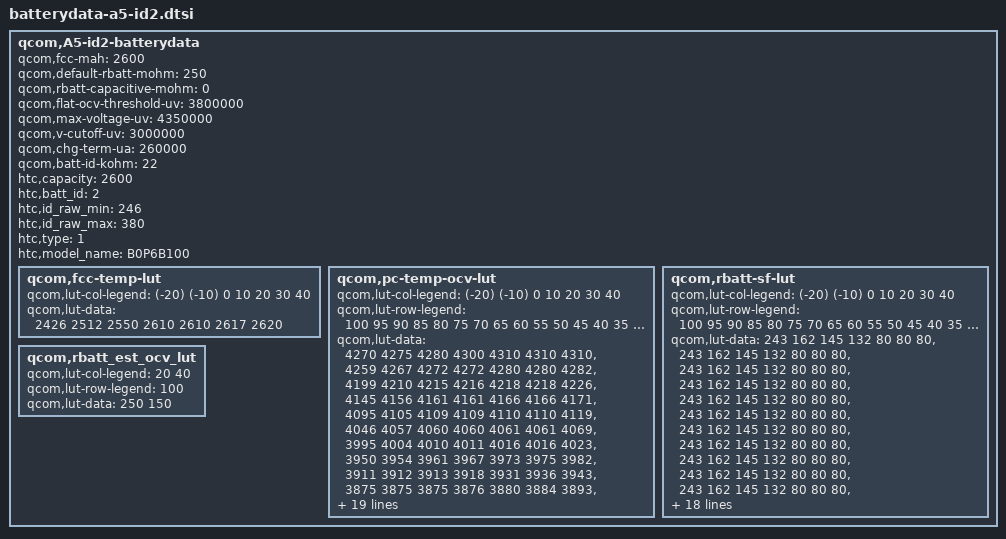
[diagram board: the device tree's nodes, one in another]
qcom,A5-id2-batterydata {
	qcom,fcc-mah = <2600>;
	qcom,default-rbatt-mohm = <250>;
	qcom,rbatt-capacitive-mohm = <0>;
	qcom,flat-ocv-threshold-uv = <3800000>;
	qcom,max-voltage-uv = <4350000>;
	qcom,v-cutoff-uv = <3000000>;
	qcom,chg-term-ua = <260000>;
	qcom,batt-id-kohm = <22>;
	htc,capacity = <2600>;
	htc,batt_id = <2>;
	htc,id_raw_min = <246>;
	htc,id_raw_max = <380>;
	htc,type = <1>;
	htc,model_name = "B0P6B100";

	qcom,fcc-temp-lut {
		qcom,lut-col-legend = <(-20) (-10) 0 10 20 30 40>;
		qcom,lut-data = <2426 2512 2550 2610 2610 2617 2620>;
	};

	qcom,pc-temp-ocv-lut {
		qcom,lut-col-legend = <(-20) (-10) 0 10 20 30 40>;
		qcom,lut-row-legend = <100 95 90 85 80 75 70 65 60 55 50 45 40 35 30 25 20 15 10 9 8 7 6 5 4 3 2 1 0>;
		qcom,lut-data = <4270 4275 4280 4300 4310 4310 4310>,
				<4259 4267 4272 4272 4280 4280 4282>,
				<4199 4210 4215 4216 4218 4218 4226>,
				<4145 4156 4161 4161 4166 4166 4171>,
				<4095 4105 4109 4109 4110 4110 4119>,
				<4046 4057 4060 4060 4061 4061 4069>,
				<3995 4004 4010 4011 4016 4016 4023>,
				<3950 3954 3961 3967 3973 3975 3982>,
				<3911 3912 3913 3918 3931 3936 3943>,
				<3875 3875 3875 3876 3880 3884 3893>,
				<3845 3845 3845 3845 3846 3849 3855>,
				<3822 3822 3822 3822 3825 3825 3830>,
				<3802 3802 3802 3802 3807 3807 3811>,
				<3786 3786 3786 3787 3792 3792 3794>,
				<3773 3773 3773 3773 3777 3777 3779>,
				<3757 3762 3762 3762 3762 3762 3764>,
				<3739 3739 3739 3739 3739 3739 3739>,
				<3710 3710 3710 3708 3708 3708 3708>,
				<3689 3689 3689 3689 3689 3689 3689>,
				<3684 3684 3684 3684 3681 3681 3681>,
				<3679 3679 3679 3679 3674 3674 3674>,
				<3673 3673 3673 3673 3667 3667 3667>,
				<3667 3667 3667 3668 3660 3660 3660>,
				<3662 3662 3662 3662 3653 3653 3653>,
				<3620 3580 3560 3543 3543 3543 3543>,
				<3520 3480 3450 3420 3420 3420 3420>,
				<3390 3350 3330 3290 3290 3290 3290>,
				<3220 3200 3180 3150 3150 3150 3150>,
				<3000 3000 3000 3000 3000 3000 3000>;
	};

	qcom,rbatt-sf-lut {
		qcom,lut-col-legend = <(-20) (-10) 0 10 20 30 40>;
		qcom,lut-row-legend = <100 95 90 85 80 75 70 65 60 55 50 45 40 35 30 25 20 15 10 9 8 7 6 5 4 3 2 1 0>;
		qcom,lut-data = <243 162 145 132 80 80 80>,
				<243 162 145 132 80 80 80>,
				<243 162 145 132 80 80 80>,
				<243 162 145 132 80 80 80>,
				<243 162 145 132 80 80 80>,
				<243 162 145 132 80 80 80>,
				<243 162 145 132 80 80 80>,
				<243 162 145 132 80 80 80>,
				<243 162 145 132 80 80 80>,
				<243 162 145 132 80 80 80>,
				<243 162 145 132 80 80 80>,
				<243 162 145 132 80 80 80>,
				<243 162 145 132 80 80 80>,
				<243 162 145 132 80 80 80>,
				<243 162 145 132 80 80 80>,
				<243 162 145 132 80 80 80>,
				<243 162 145 132 80 80 80>,
				<243 162 145 132 80 80 80>,
				<243 162 145 132 80 80 80>,
				<243 162 145 132 80 80 80>,
				<243 162 145 132 80 80 80>,
				<243 162 145 132 80 80 80>,
				<243 162 145 132 80 80 80>,
				<243 162 145 132 80 80 80>,
				<243 162 145 132 80 80 80>,
				<243 162 145 132 80 80 80>,
				<243 162 145 132 80 80 80>,
				<243 162 145 132 80 80 80>,
				<243 162 145 132 80 80 80>;
	};

	qcom,rbatt_est_ocv_lut {
		qcom,lut-col-legend = <20 40>;
		qcom,lut-row-legend = <100>;
		qcom,lut-data = <250 150>;
	};
};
